# SD14_Module_1 register map
Vendor: Texas Instruments
Peripheral module from a debugger description file (folder msp430).
Registers are 16-bit, access not given, no defined reset value unless marked. A register's access mark holds for its fields unless they carry their own. Offsets are as the file gives them; lines under a group give offsets from that group; [hi:lo] are bit positions; {n}, {i} and the like mark numbered series; 'fields as' and 'values as' point back to an identical list; <NAME> marks a mode.

## SD14_Module
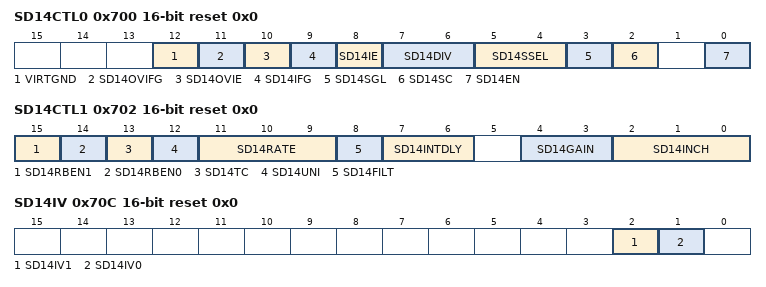
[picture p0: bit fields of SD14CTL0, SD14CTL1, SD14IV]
0x700 SD14CTL0 rw reset 0x0 — SD14 Control Register 0
  [12] VIRTGND — Defines virtual ground
  [11] SD14OVIFG — SD14 overflow interrupt flag
  [10] SD14OVIE — SD14 overflow interrupt enable
  [9] SD14IFG — SD14 interrupt flag
  [8] SD14IE — SD14 interrupt enable
  [7:6] SD14DIV — SD14 Sigma-Delta Clock divider Bit: 0
    {v}=SD14 Sigma-Delta Clock divider select: {v} (v=0..3)
  [5:4] SD14SSEL — SD14 Sigma-Delta Clock source Bit: 0
    {v}=SD14 Sigma-Delta Clock select: {v} (v=0..3)
  [3] SD14SGL — SD14 Conversion mode select
  [2] SD14SC — SD14 Enable transmission of uplink
  [0] SD14EN — SD14 Module enable
0x702 SD14CTL1 rw reset 0x0 — SD14 Control Register 1
  [15] SD14RBEN1 — SD14 Resistive bias on TEMP2 enable
  [14] SD14RBEN0 — SD14 Resistive bias on TEMP1 enable
  [13] SD14TC — SD14 Two's complement format enable Bit: 0
  [12] SD14UNI — SD14 Unipolar format enable Bit: 0
  [11:9] SD14RATE — SD14 rate change factor selection Bit: 0
    {v}=SD14 rate change factor: {v} (v=0..7)
  [8] SD14FILT — SD14 digital filter selection
  [7:6] SD14INTDLY — SD14 Interrupt delay Bit: 0
    {v}=SD14 Interrupt delay select: {v} (v=0..3)
  [4:3] SD14GAIN — SD14 preamplifier gain Bit: 0
    {v}=SD14 preamplifier gain select: {v} (v=0..3)
  [2:0] SD14INCH — SD14 channel input selection Bit: 0
    {v}=SD14 channel input select: {v} (v=0..7)
0x704 SD14MEM0 — SD14 Conversion Result
{0x704+2i} SD14MEM{i} (i=1..3) — SD14 Intermediate Conversion Result
0x70C SD14IV rw reset 0x0 — SD14 Interrupt Vector
  [2] SD14IV1 — SD14IV Interrupt vector value bit: 1
  [1] SD14IV0 — SD14IV Interrupt vector value bit: 0
